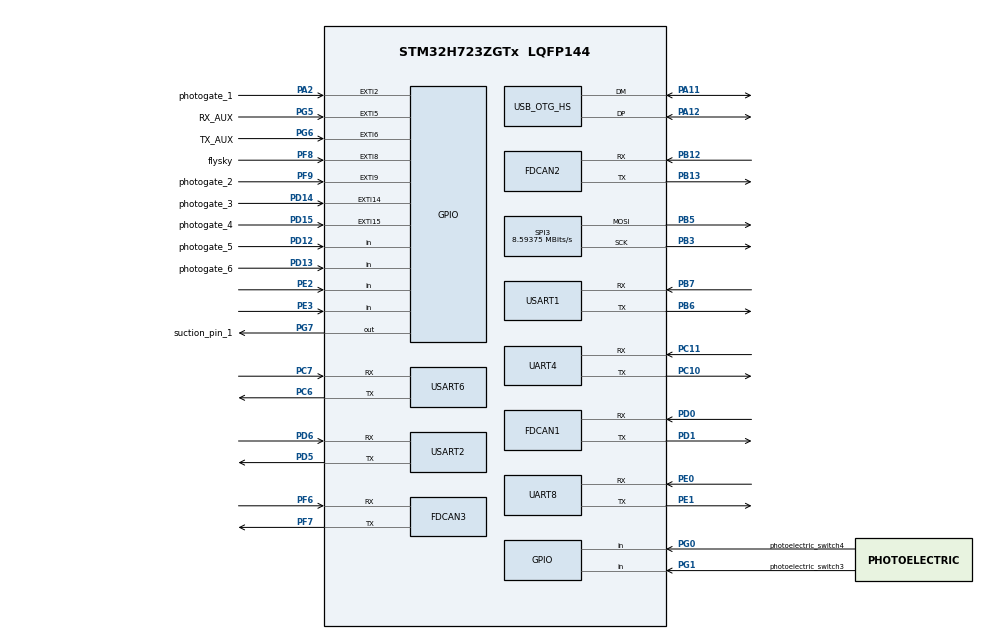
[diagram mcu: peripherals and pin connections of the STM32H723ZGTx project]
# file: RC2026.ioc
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CORTEX_M7.AccessPermission_S-Cortex_Memory_Protection_Unit_Region1_Settings_S=MPU_REGION_PRIV_RO
CORTEX_M7.AccessPermission_S-Cortex_Memory_Protection_Unit_Region2_Settings_S=MPU_REGION_PRIV_RW
CORTEX_M7.AccessPermission_Spec=MPU_REGION_NO_ACCESS
CORTEX_M7.BaseAddress_S-Cortex_Memory_Protection_Unit_Region1_Settings_S=0x08000000
CORTEX_M7.BaseAddress_S-Cortex_Memory_Protection_Unit_Region2_Settings_S=0x20000000
CORTEX_M7.BaseAddress_Spec=0x00000000
CORTEX_M7.CPU_DCache=Enabled
CORTEX_M7.CPU_ICache=Enabled
CORTEX_M7.DisableExec_S-Cortex_Memory_Protection_Unit_Region2_Settings_S=MPU_INSTRUCTION_ACCESS_DISABLE
CORTEX_M7.Enable_S-Cortex_Memory_Protection_Unit_Region1_Settings_S=MPU_REGION_ENABLE
CORTEX_M7.Enable_S-Cortex_Memory_Protection_Unit_Region2_Settings_S=MPU_REGION_ENABLE
CORTEX_M7.IsBufferable_S-Cortex_Memory_Protection_Unit_Region2_Settings_S=MPU_ACCESS_BUFFERABLE
CORTEX_M7.IsCacheable_S-Cortex_Memory_Protection_Unit_Region1_Settings_S=MPU_ACCESS_CACHEABLE
CORTEX_M7.IsCacheable_S-Cortex_Memory_Protection_Unit_Region2_Settings_S=MPU_ACCESS_CACHEABLE
CORTEX_M7.IsCacheable_Spec=MPU_ACCESS_NOT_CACHEABLE
CORTEX_M7.Size_S-Cortex_Memory_Protection_Unit_Region1_Settings_S=MPU_REGION_SIZE_1MB
CORTEX_M7.Size_S-Cortex_Memory_Protection_Unit_Region2_Settings_S=MPU_REGION_SIZE_512KB
CORTEX_M7.Size_Spec=MPU_REGION_SIZE_4GB
CORTEX_M7.SubRegionDisable_Spec=0x87
CORTEX_M7.TypeExtField_S-Cortex_Memory_Protection_Unit_Region1_Settings_S=MPU_TEX_LEVEL1
CORTEX_M7.TypeExtField_S-Cortex_Memory_Protection_Unit_Region2_Settings_S=MPU_TEX_LEVEL1
CORTEX_M7.TypeExtField_Spec=MPU_TEX_LEVEL0
CORTEX_M7.default_mode_Activation=1
Dma.CORDIC_RD.2.Direction=DMA_PERIPH_TO_MEMORY
Dma.CORDIC_RD.2.EventEnable=DISABLE
Dma.CORDIC_RD.2.FIFOMode=DMA_FIFOMODE_DISABLE
Dma.CORDIC_RD.2.Instance=DMA1_Stream4
Dma.CORDIC_RD.2.MemDataAlignment=DMA_MDATAALIGN_BYTE
Dma.CORDIC_RD.2.MemInc=DMA_MINC_ENABLE
Dma.CORDIC_RD.2.Mode=DMA_NORMAL
Dma.CORDIC_RD.2.PeriphDataAlignment=DMA_PDATAALIGN_BYTE
Dma.CORDIC_RD.2.PeriphInc=DMA_PINC_DISABLE
Dma.CORDIC_RD.2.Polarity=HAL_DMAMUX_REQ_GEN_RISING
Dma.CORDIC_RD.2.Priority=DMA_PRIORITY_LOW
Dma.CORDIC_RD.2.RequestNumber=1
Dma.CORDIC_RD.2.SignalID=NONE
Dma.CORDIC_RD.2.SyncEnable=DISABLE
Dma.CORDIC_RD.2.SyncPolarity=HAL_DMAMUX_SYNC_NO_EVENT
Dma.CORDIC_RD.2.SyncRequestNumber=1
Dma.CORDIC_RD.2.SyncSignalID=NONE
Dma.CORDIC_WR.3.Direction=DMA_MEMORY_TO_PERIPH
Dma.CORDIC_WR.3.EventEnable=DISABLE
Dma.CORDIC_WR.3.FIFOMode=DMA_FIFOMODE_DISABLE
Dma.CORDIC_WR.3.Instance=DMA1_Stream5
Dma.CORDIC_WR.3.MemDataAlignment=DMA_MDATAALIGN_BYTE
Dma.CORDIC_WR.3.MemInc=DMA_MINC_ENABLE
Dma.CORDIC_WR.3.Mode=DMA_NORMAL
Dma.CORDIC_WR.3.PeriphDataAlignment=DMA_PDATAALIGN_BYTE
Dma.CORDIC_WR.3.PeriphInc=DMA_PINC_DISABLE
Dma.CORDIC_WR.3.Polarity=HAL_DMAMUX_REQ_GEN_RISING
Dma.CORDIC_WR.3.Priority=DMA_PRIORITY_LOW
Dma.CORDIC_WR.3.RequestNumber=1
Dma.CORDIC_WR.3.SignalID=NONE
Dma.CORDIC_WR.3.SyncEnable=DISABLE
Dma.CORDIC_WR.3.SyncPolarity=HAL_DMAMUX_SYNC_NO_EVENT
Dma.CORDIC_WR.3.SyncRequestNumber=1
Dma.CORDIC_WR.3.SyncSignalID=NONE
Dma.Request0=USART1_RX
Dma.Request1=USART1_TX
Dma.Request10=UART4_RX
Dma.Request11=UART4_TX
Dma.Request12=SPI3_TX
Dma.Request2=CORDIC_RD
Dma.Request3=CORDIC_WR
Dma.Request4=UART8_RX
Dma.Request5=UART8_TX
Dma.Request6=USART2_RX
Dma.Request7=USART2_TX
Dma.Request8=USART6_RX
Dma.Request9=USART6_TX
Dma.SPI3_TX.12.Direction=DMA_MEMORY_TO_PERIPH
Dma.SPI3_TX.12.EventEnable=DISABLE
Dma.SPI3_TX.12.FIFOMode=DMA_FIFOMODE_DISABLE
Dma.SPI3_TX.12.Instance=DMA2_Stream4
Dma.SPI3_TX.12.MemDataAlignment=DMA_MDATAALIGN_BYTE
Dma.SPI3_TX.12.MemInc=DMA_MINC_ENABLE
Dma.SPI3_TX.12.Mode=DMA_NORMAL
Dma.SPI3_TX.12.PeriphDataAlignment=DMA_PDATAALIGN_BYTE
Dma.SPI3_TX.12.PeriphInc=DMA_PINC_DISABLE
Dma.SPI3_TX.12.Polarity=HAL_DMAMUX_REQ_GEN_RISING
Dma.SPI3_TX.12.Priority=DMA_PRIORITY_LOW
Dma.SPI3_TX.12.RequestNumber=1
Dma.SPI3_TX.12.SignalID=NONE
Dma.SPI3_TX.12.SyncEnable=DISABLE
Dma.SPI3_TX.12.SyncPolarity=HAL_DMAMUX_SYNC_NO_EVENT
Dma.SPI3_TX.12.SyncRequestNumber=1
Dma.SPI3_TX.12.SyncSignalID=NONE
Dma.UART4_RX.10.Direction=DMA_PERIPH_TO_MEMORY
Dma.UART4_RX.10.EventEnable=DISABLE
Dma.UART4_RX.10.FIFOMode=DMA_FIFOMODE_DISABLE
Dma.UART4_RX.10.Instance=DMA1_Stream2
Dma.UART4_RX.10.MemDataAlignment=DMA_MDATAALIGN_BYTE
Dma.UART4_RX.10.MemInc=DMA_MINC_ENABLE
Dma.UART4_RX.10.Mode=DMA_NORMAL
Dma.UART4_RX.10.PeriphDataAlignment=DMA_PDATAALIGN_BYTE
Dma.UART4_RX.10.PeriphInc=DMA_PINC_DISABLE
Dma.UART4_RX.10.Polarity=HAL_DMAMUX_REQ_GEN_RISING
Dma.UART4_RX.10.Priority=DMA_PRIORITY_LOW
Dma.UART4_RX.10.RequestNumber=1
Dma.UART4_RX.10.SignalID=NONE
Dma.UART4_RX.10.SyncEnable=DISABLE
Dma.UART4_RX.10.SyncPolarity=HAL_DMAMUX_SYNC_NO_EVENT
Dma.UART4_RX.10.SyncRequestNumber=1
Dma.UART4_RX.10.SyncSignalID=NONE
Dma.UART4_TX.11.Direction=DMA_MEMORY_TO_PERIPH
Dma.UART4_TX.11.EventEnable=DISABLE
Dma.UART4_TX.11.FIFOMode=DMA_FIFOMODE_DISABLE
Dma.UART4_TX.11.Instance=DMA1_Stream3
Dma.UART4_TX.11.MemDataAlignment=DMA_MDATAALIGN_BYTE
Dma.UART4_TX.11.MemInc=DMA_MINC_ENABLE
Dma.UART4_TX.11.Mode=DMA_NORMAL
Dma.UART4_TX.11.PeriphDataAlignment=DMA_PDATAALIGN_BYTE
Dma.UART4_TX.11.PeriphInc=DMA_PINC_DISABLE
Dma.UART4_TX.11.Polarity=HAL_DMAMUX_REQ_GEN_RISING
Dma.UART4_TX.11.Priority=DMA_PRIORITY_LOW
Dma.UART4_TX.11.RequestNumber=1
Dma.UART4_TX.11.SignalID=NONE
Dma.UART4_TX.11.SyncEnable=DISABLE
Dma.UART4_TX.11.SyncPolarity=HAL_DMAMUX_SYNC_NO_EVENT
Dma.UART4_TX.11.SyncRequestNumber=1
Dma.UART4_TX.11.SyncSignalID=NONE
Dma.UART8_RX.4.Direction=DMA_PERIPH_TO_MEMORY
Dma.UART8_RX.4.EventEnable=DISABLE
Dma.UART8_RX.4.FIFOMode=DMA_FIFOMODE_DISABLE
Dma.UART8_RX.4.Instance=DMA1_Stream6
Dma.UART8_RX.4.MemDataAlignment=DMA_MDATAALIGN_BYTE
Dma.UART8_RX.4.MemInc=DMA_MINC_ENABLE
Dma.UART8_RX.4.Mode=DMA_NORMAL
Dma.UART8_RX.4.PeriphDataAlignment=DMA_PDATAALIGN_BYTE
Dma.UART8_RX.4.PeriphInc=DMA_PINC_DISABLE
Dma.UART8_RX.4.Polarity=HAL_DMAMUX_REQ_GEN_RISING
Dma.UART8_RX.4.Priority=DMA_PRIORITY_LOW
Dma.UART8_RX.4.RequestNumber=1
Dma.UART8_RX.4.SignalID=NONE
Dma.UART8_RX.4.SyncEnable=DISABLE
Dma.UART8_RX.4.SyncPolarity=HAL_DMAMUX_SYNC_NO_EVENT
Dma.UART8_RX.4.SyncRequestNumber=1
Dma.UART8_RX.4.SyncSignalID=NONE
Dma.UART8_TX.5.Direction=DMA_MEMORY_TO_PERIPH
Dma.UART8_TX.5.EventEnable=DISABLE
Dma.UART8_TX.5.FIFOMode=DMA_FIFOMODE_DISABLE
Dma.UART8_TX.5.Instance=DMA1_Stream7
Dma.UART8_TX.5.MemDataAlignment=DMA_MDATAALIGN_BYTE
Dma.UART8_TX.5.MemInc=DMA_MINC_ENABLE
Dma.UART8_TX.5.Mode=DMA_NORMAL
Dma.UART8_TX.5.PeriphDataAlignment=DMA_PDATAALIGN_BYTE
Dma.UART8_TX.5.PeriphInc=DMA_PINC_DISABLE
Dma.UART8_TX.5.Polarity=HAL_DMAMUX_REQ_GEN_RISING
Dma.UART8_TX.5.Priority=DMA_PRIORITY_LOW
Dma.UART8_TX.5.RequestNumber=1
Dma.UART8_TX.5.SignalID=NONE
Dma.UART8_TX.5.SyncEnable=DISABLE
Dma.UART8_TX.5.SyncPolarity=HAL_DMAMUX_SYNC_NO_EVENT
Dma.UART8_TX.5.SyncRequestNumber=1
Dma.UART8_TX.5.SyncSignalID=NONE
Dma.USART1_RX.0.Direction=DMA_PERIPH_TO_MEMORY
Dma.USART1_RX.0.EventEnable=DISABLE
Dma.USART1_RX.0.FIFOMode=DMA_FIFOMODE_DISABLE
Dma.USART1_RX.0.Instance=DMA1_Stream0
Dma.USART1_RX.0.MemDataAlignment=DMA_MDATAALIGN_BYTE
Dma.USART1_RX.0.MemInc=DMA_MINC_ENABLE
Dma.USART1_RX.0.Mode=DMA_NORMAL
Dma.USART1_RX.0.PeriphDataAlignment=DMA_PDATAALIGN_BYTE
Dma.USART1_RX.0.PeriphInc=DMA_PINC_DISABLE
Dma.USART1_RX.0.Polarity=HAL_DMAMUX_REQ_GEN_RISING
Dma.USART1_RX.0.Priority=DMA_PRIORITY_LOW
Dma.USART1_RX.0.RequestNumber=1
Dma.USART1_RX.0.SignalID=NONE
Dma.USART1_RX.0.SyncEnable=DISABLE
Dma.USART1_RX.0.SyncPolarity=HAL_DMAMUX_SYNC_NO_EVENT
Dma.USART1_RX.0.SyncRequestNumber=1
Dma.USART1_RX.0.SyncSignalID=NONE
Dma.USART1_TX.1.Direction=DMA_MEMORY_TO_PERIPH
Dma.USART1_TX.1.EventEnable=DISABLE
Dma.USART1_TX.1.FIFOMode=DMA_FIFOMODE_DISABLE
Dma.USART1_TX.1.Instance=DMA1_Stream1
Dma.USART1_TX.1.MemDataAlignment=DMA_MDATAALIGN_BYTE
Dma.USART1_TX.1.MemInc=DMA_MINC_ENABLE
Dma.USART1_TX.1.Mode=DMA_NORMAL
Dma.USART1_TX.1.PeriphDataAlignment=DMA_PDATAALIGN_BYTE
Dma.USART1_TX.1.PeriphInc=DMA_PINC_DISABLE
Dma.USART1_TX.1.Polarity=HAL_DMAMUX_REQ_GEN_RISING
Dma.USART1_TX.1.Priority=DMA_PRIORITY_LOW
Dma.USART1_TX.1.RequestNumber=1
Dma.USART1_TX.1.SignalID=NONE
Dma.USART1_TX.1.SyncEnable=DISABLE
Dma.USART1_TX.1.SyncPolarity=HAL_DMAMUX_SYNC_NO_EVENT
Dma.USART1_TX.1.SyncRequestNumber=1
Dma.USART1_TX.1.SyncSignalID=NONE
Dma.USART2_RX.6.Direction=DMA_PERIPH_TO_MEMORY
Dma.USART2_RX.6.EventEnable=DISABLE
Dma.USART2_RX.6.FIFOMode=DMA_FIFOMODE_DISABLE
Dma.USART2_RX.6.Instance=DMA2_Stream0
Dma.USART2_RX.6.MemDataAlignment=DMA_MDATAALIGN_BYTE
Dma.USART2_RX.6.MemInc=DMA_MINC_ENABLE
Dma.USART2_RX.6.Mode=DMA_NORMAL
Dma.USART2_RX.6.PeriphDataAlignment=DMA_PDATAALIGN_BYTE
Dma.USART2_RX.6.PeriphInc=DMA_PINC_DISABLE
Dma.USART2_RX.6.Polarity=HAL_DMAMUX_REQ_GEN_RISING
Dma.USART2_RX.6.Priority=DMA_PRIORITY_LOW
Dma.USART2_RX.6.RequestNumber=1
Dma.USART2_RX.6.SignalID=NONE
Dma.USART2_RX.6.SyncEnable=DISABLE
Dma.USART2_RX.6.SyncPolarity=HAL_DMAMUX_SYNC_NO_EVENT
Dma.USART2_RX.6.SyncRequestNumber=1
Dma.USART2_RX.6.SyncSignalID=NONE
Dma.USART2_TX.7.Direction=DMA_MEMORY_TO_PERIPH
Dma.USART2_TX.7.EventEnable=DISABLE
Dma.USART2_TX.7.FIFOMode=DMA_FIFOMODE_DISABLE
Dma.USART2_TX.7.Instance=DMA2_Stream1
Dma.USART2_TX.7.MemDataAlignment=DMA_MDATAALIGN_BYTE
Dma.USART2_TX.7.MemInc=DMA_MINC_ENABLE
Dma.USART2_TX.7.Mode=DMA_NORMAL
Dma.USART2_TX.7.PeriphDataAlignment=DMA_PDATAALIGN_BYTE
Dma.USART2_TX.7.PeriphInc=DMA_PINC_DISABLE
Dma.USART2_TX.7.Polarity=HAL_DMAMUX_REQ_GEN_RISING
Dma.USART2_TX.7.Priority=DMA_PRIORITY_LOW
Dma.USART2_TX.7.RequestNumber=1
Dma.USART2_TX.7.SignalID=NONE
Dma.USART2_TX.7.SyncEnable=DISABLE
Dma.USART2_TX.7.SyncPolarity=HAL_DMAMUX_SYNC_NO_EVENT
Dma.USART2_TX.7.SyncRequestNumber=1
Dma.USART2_TX.7.SyncSignalID=NONE
Dma.USART6_RX.8.Direction=DMA_PERIPH_TO_MEMORY
Dma.USART6_RX.8.EventEnable=DISABLE
Dma.USART6_RX.8.FIFOMode=DMA_FIFOMODE_DISABLE
Dma.USART6_RX.8.Instance=DMA2_Stream2
Dma.USART6_RX.8.MemDataAlignment=DMA_MDATAALIGN_BYTE
Dma.USART6_RX.8.MemInc=DMA_MINC_ENABLE
Dma.USART6_RX.8.Mode=DMA_NORMAL
Dma.USART6_RX.8.PeriphDataAlignment=DMA_PDATAALIGN_BYTE
Dma.USART6_RX.8.PeriphInc=DMA_PINC_DISABLE
Dma.USART6_RX.8.Polarity=HAL_DMAMUX_REQ_GEN_RISING
Dma.USART6_RX.8.Priority=DMA_PRIORITY_LOW
Dma.USART6_RX.8.RequestNumber=1
Dma.USART6_RX.8.SignalID=NONE
Dma.USART6_RX.8.SyncEnable=DISABLE
Dma.USART6_RX.8.SyncPolarity=HAL_DMAMUX_SYNC_NO_EVENT
Dma.USART6_RX.8.SyncRequestNumber=1
Dma.USART6_RX.8.SyncSignalID=NONE
Dma.USART6_TX.9.Direction=DMA_MEMORY_TO_PERIPH
Dma.USART6_TX.9.EventEnable=DISABLE
Dma.USART6_TX.9.FIFOMode=DMA_FIFOMODE_DISABLE
Dma.USART6_TX.9.Instance=DMA2_Stream3
Dma.USART6_TX.9.MemDataAlignment=DMA_MDATAALIGN_BYTE
Dma.USART6_TX.9.MemInc=DMA_MINC_ENABLE
Dma.USART6_TX.9.Mode=DMA_NORMAL
Dma.USART6_TX.9.PeriphDataAlignment=DMA_PDATAALIGN_BYTE
Dma.USART6_TX.9.PeriphInc=DMA_PINC_DISABLE
Dma.USART6_TX.9.Polarity=HAL_DMAMUX_REQ_GEN_RISING
Dma.USART6_TX.9.Priority=DMA_PRIORITY_LOW
Dma.USART6_TX.9.RequestNumber=1
Dma.USART6_TX.9.SignalID=NONE
Dma.USART6_TX.9.SyncEnable=DISABLE
Dma.USART6_TX.9.SyncPolarity=HAL_DMAMUX_SYNC_NO_EVENT
Dma.USART6_TX.9.SyncRequestNumber=1
Dma.USART6_TX.9.SyncSignalID=NONE
FDCAN1.CalculateBaudRateNominal=1000000
FDCAN1.CalculateTimeBitNominal=1000
FDCAN1.CalculateTimeQuantumNominal=40.0
FDCAN1.DataPrescaler=1
FDCAN1.DataSyncJumpWidth=2
FDCAN1.DataTimeSeg1=15
FDCAN1.DataTimeSeg2=9
FDCAN1.ExtFiltersNbr=2
FDCAN1.NominalPrescaler=1
FDCAN1.NominalSyncJumpWidth=2
FDCAN1.NominalTimeSeg1=15
FDCAN1.NominalTimeSeg2=9
FDCAN1.ProtocolException=DISABLE
FDCAN1.RxBuffersNbr=0
FDCAN1.RxFifo0ElmtsNbr=8
FDCAN1.RxFifo1ElmtsNbr=8
FDCAN1.StdFiltersNbr=2
FDCAN1.TxBuffersNbr=29
FDCAN1.TxFifoQueueElmtsNbr=3
FDCAN2.CalculateBaudRateNominal=1000000
FDCAN2.CalculateTimeBitNominal=1000
FDCAN2.CalculateTimeQuantumNominal=40.0
FDCAN2.DataPrescaler=1
FDCAN2.DataSyncJumpWidth=2
FDCAN2.DataTimeSeg1=15
FDCAN2.DataTimeSeg2=9
FDCAN2.ExtFiltersNbr=2
FDCAN2.MessageRAMOffset=0x400
FDCAN2.NominalPrescaler=1
FDCAN2.NominalSyncJumpWidth=2
FDCAN2.NominalTimeSeg1=15
FDCAN2.NominalTimeSeg2=9
FDCAN2.ProtocolException=DISABLE
FDCAN2.RxBuffersNbr=0
FDCAN2.RxFifo0ElmtsNbr=8
FDCAN2.RxFifo1ElmtsNbr=8
FDCAN2.StdFiltersNbr=2
FDCAN2.TxBuffersNbr=29
FDCAN2.TxFifoQueueElmtsNbr=3
FDCAN3.CalculateBaudRateNominal=1000000
FDCAN3.CalculateTimeBitNominal=1000
FDCAN3.CalculateTimeQuantumNominal=40.0
FDCAN3.DataSyncJumpWidth=2
FDCAN3.DataTimeSeg1=15
FDCAN3.DataTimeSeg2=9
FDCAN3.ExtFiltersNbr=2
FDCAN3.MessageRAMOffset=0x800
FDCAN3.NominalPrescaler=1
FDCAN3.NominalSyncJumpWidth=2
FDCAN3.NominalTimeSeg1=15
FDCAN3.NominalTimeSeg2=9
FDCAN3.RxBuffersNbr=0
FDCAN3.RxFifo0ElmtsNbr=8
FDCAN3.RxFifo1ElmtsNbr=8
FDCAN3.StdFiltersNbr=2
FDCAN3.TxBuffersNbr=29
FDCAN3.TxFifoQueueElmtsNbr=3
FREERTOS.Tasks01=defaultTask,24,128,StartDefaultTask,Default,NULL,Dynamic,NULL,NULL
Mcu.Family=STM32H7
Mcu.Name=STM32H723ZGTx
Mcu.Package=LQFP144
NVIC.CORDIC_IRQn=true\:5\:0\:false\:false\:true\:true\:true\:true\:true
NVIC.DMA1_Stream0_IRQn=true\:5\:0\:false\:false\:true\:true\:false\:true\:true
NVIC.DMA1_Stream1_IRQn=true\:5\:0\:false\:false\:true\:true\:false\:true\:true
NVIC.DMA1_Stream2_IRQn=true\:5\:0\:false\:false\:true\:true\:false\:true\:true
NVIC.DMA1_Stream3_IRQn=true\:5\:0\:false\:false\:true\:true\:false\:true\:true
NVIC.DMA1_Stream4_IRQn=true\:5\:0\:false\:false\:true\:true\:false\:true\:true
NVIC.DMA1_Stream5_IRQn=true\:5\:0\:false\:false\:true\:true\:false\:true\:true
NVIC.DMA1_Stream6_IRQn=true\:5\:0\:false\:false\:true\:true\:false\:true\:true
NVIC.DMA1_Stream7_IRQn=true\:5\:0\:false\:false\:true\:true\:false\:true\:true
NVIC.DMA2_Stream0_IRQn=true\:5\:0\:false\:false\:true\:true\:false\:true\:true
NVIC.DMA2_Stream1_IRQn=true\:5\:0\:false\:false\:true\:true\:false\:true\:true
NVIC.DMA2_Stream2_IRQn=true\:5\:0\:false\:false\:true\:true\:false\:true\:true
NVIC.DMA2_Stream3_IRQn=true\:5\:0\:false\:false\:true\:true\:false\:true\:true
NVIC.DMA2_Stream4_IRQn=true\:5\:0\:false\:false\:true\:true\:false\:true\:true
NVIC.EXTI15_10_IRQn=true\:4\:0\:true\:false\:true\:false\:true\:true\:true
NVIC.EXTI2_IRQn=true\:4\:0\:true\:false\:true\:false\:true\:true\:true
NVIC.EXTI9_5_IRQn=true\:4\:0\:true\:false\:true\:false\:true\:true\:true
NVIC.FDCAN1_IT0_IRQn=true\:5\:0\:false\:false\:true\:true\:true\:true\:true
NVIC.FDCAN1_IT1_IRQn=true\:5\:0\:false\:false\:true\:true\:true\:true\:true
NVIC.FDCAN2_IT0_IRQn=true\:5\:0\:false\:false\:true\:true\:true\:true\:true
NVIC.FDCAN2_IT1_IRQn=true\:5\:0\:false\:false\:true\:true\:true\:true\:true
NVIC.FDCAN3_IT0_IRQn=true\:5\:0\:false\:false\:true\:true\:true\:true\:true
NVIC.FDCAN3_IT1_IRQn=true\:5\:0\:false\:false\:true\:true\:true\:true\:true
NVIC.OTG_HS_IRQn=true\:5\:0\:false\:false\:true\:true\:false\:true\:true
NVIC.PriorityGroup=NVIC_PRIORITYGROUP_4
NVIC.SPI3_IRQn=true\:5\:0\:false\:false\:true\:true\:false\:true\:true
NVIC.TIM2_IRQn=true\:5\:0\:false\:false\:true\:true\:true\:true\:true
NVIC.TIM4_IRQn=true\:3\:0\:true\:false\:true\:false\:true\:true\:true
NVIC.TIM6_DAC_IRQn=true\:15\:0\:false\:false\:true\:false\:false\:true\:true
NVIC.TIM7_IRQn=true\:7\:0\:true\:false\:true\:false\:true\:true\:true
NVIC.TIM8_UP_TIM13_IRQn=true\:7\:0\:true\:false\:true\:false\:true\:true\:true
NVIC.TimeBase=TIM6_DAC_IRQn
NVIC.TimeBaseIP=TIM6
NVIC.UART4_IRQn=true\:5\:0\:false\:false\:true\:true\:true\:true\:true
NVIC.UART8_IRQn=true\:5\:0\:false\:false\:true\:true\:true\:true\:true
NVIC.USART1_IRQn=true\:5\:0\:false\:false\:true\:false\:true\:true\:true
NVIC.USART2_IRQn=true\:5\:0\:false\:false\:true\:true\:true\:true\:true
NVIC.USART6_IRQn=true\:5\:0\:false\:false\:true\:true\:true\:true\:true
PA11.Mode=Device_Only_FS
PA11.Signal=USB_OTG_HS_DM
PA12.Mode=Device_Only_FS
PA12.Signal=USB_OTG_HS_DP
PA13(JTMS/SWDIO).Mode=Serial_Wire
PA13(JTMS/SWDIO).Signal=DEBUG_JTMS-SWDIO
PA14(JTCK/SWCLK).Mode=Serial_Wire
PA14(JTCK/SWCLK).Signal=DEBUG_JTCK-SWCLK
PA2.GPIO_Label=photogate_1
PA2.GPIO_PuPd=GPIO_PULLUP
PA2.Signal=GPXTI2
PB12.Mode=FDCAN_Activate
PB12.Signal=FDCAN2_RX
PB13.Mode=FDCAN_Activate
PB13.Signal=FDCAN2_TX
PB3(JTDO/TRACESWO).GPIO_Speed=GPIO_SPEED_FREQ_VERY_HIGH
PB3(JTDO/TRACESWO).Mode=TX_Only_Simplex_Unidirect_Master
PB3(JTDO/TRACESWO).Signal=SPI3_SCK
PB5.GPIO_Speed=GPIO_SPEED_FREQ_VERY_HIGH
PB5.Mode=TX_Only_Simplex_Unidirect_Master
PB5.Signal=SPI3_MOSI
PB6.Mode=Asynchronous
PB6.Signal=USART1_TX
PB7.Mode=Asynchronous
PB7.Signal=USART1_RX
PC10.Mode=Asynchronous
PC10.Signal=UART4_TX
PC11.Mode=Asynchronous
PC11.Signal=UART4_RX
PC6.Mode=Asynchronous
PC6.Signal=USART6_TX
PC7.Mode=Asynchronous
PC7.Signal=USART6_RX
PD0.Mode=FDCAN_Activate
PD0.Signal=FDCAN1_RX
PD1.Mode=FDCAN_Activate
PD1.Signal=FDCAN1_TX
PD12.GPIO_Label=photogate_5
PD12.GPIO_PuPd=GPIO_PULLUP
PD12.Signal=GPIO_Input
PD13.GPIO_Label=photogate_6
PD13.GPIO_PuPd=GPIO_PULLUP
PD13.Signal=GPIO_Input
PD14.GPIO_Label=photogate_3
PD14.GPIO_PuPd=GPIO_PULLUP
PD14.Signal=GPXTI14
PD15.GPIO_Label=photogate_4
PD15.GPIO_PuPd=GPIO_PULLUP
PD15.Signal=GPXTI15
PD5.Mode=Asynchronous
PD5.Signal=USART2_TX
PD6.Mode=Asynchronous
PD6.Signal=USART2_RX
PE0.Mode=Asynchronous
PE0.Signal=UART8_RX
PE1.Mode=Asynchronous
PE1.Signal=UART8_TX
PE2.GPIO_PuPd=GPIO_PULLUP
PE2.Signal=GPIO_Input
PE3.GPIO_PuPd=GPIO_PULLUP
PE3.Signal=GPIO_Input
PF6.Mode=FDCAN_Activate
PF6.Signal=FDCAN3_RX
PF7.Mode=FDCAN_Activate
PF7.Signal=FDCAN3_TX
PF8.GPIO_Label=flysky
PF8.GPIO_PuPd=GPIO_NOPULL
PF8.Signal=GPXTI8
PF9.GPIO_Label=photogate_2
PF9.GPIO_PuPd=GPIO_PULLUP
PF9.Signal=GPXTI9
PG0.GPIO_Label=photoelectric_switch4
PG0.GPIO_PuPd=GPIO_PULLUP
PG0.Signal=GPIO_Input
PG1.GPIO_Label=photoelectric_switch3
PG1.GPIO_PuPd=GPIO_PULLUP
PG1.Signal=GPIO_Input
PG5.GPIO_Label=RX_AUX
PG5.GPIO_PuPd=GPIO_PULLDOWN
PG5.Signal=GPXTI5
PG6.GPIO_Label=TX_AUX
PG6.GPIO_PuPd=GPIO_PULLDOWN
PG6.Signal=GPXTI6
PG7.GPIO_Label=suction_pin_1
PG7.GPIO_ModeDefaultOutputPP=GPIO_MODE_OUTPUT_PP
PG7.GPIO_Speed=GPIO_SPEED_FREQ_HIGH
PG7.PinState=GPIO_PIN_RESET
PG7.Signal=GPIO_Output
PH0-OSC_IN.Mode=HSE-External-Oscillator
PH0-OSC_IN.Signal=RCC_OSC_IN
PH1-OSC_OUT.Mode=HSE-External-Oscillator
PH1-OSC_OUT.Signal=RCC_OSC_OUT
ProjectManager.HeapSize=0x200
ProjectManager.StackSize=0x400
ProjectManager.TargetToolchain=MDK-ARM V5.32
RCC.ADCFreq_Value=50390625
RCC.APB1Freq_Value=137500000
RCC.APB2Freq_Value=137500000
RCC.APB3Freq_Value=137500000
RCC.APB4Freq_Value=137500000
RCC.CortexFreq_Value=550000000
RCC.D1PPRE=RCC_APB3_DIV2
RCC.D2PPRE1=RCC_APB1_DIV2
RCC.D2PPRE2=RCC_APB2_DIV2
RCC.D3PPRE=RCC_APB4_DIV2
RCC.DIVM1=2
RCC.DIVN1=44
RCC.DIVP1=1
RCC.DIVQ1=4
RCC.FDCANCLockSelection=RCC_FDCANCLKSOURCE_HSE
RCC.HCLKFreq_Value=275000000
RCC.HPRE=RCC_HCLK_DIV2
RCC.PLL2FRACN=0
RCC.PLL3FRACN=0
RCC.PLLFRACN=0
RCC.PLLSourceVirtual=RCC_PLLSOURCE_HSE
RCC.SYSCLKFreq_VALUE=550000000
RCC.SYSCLKSource=RCC_SYSCLKSOURCE_PLLCLK
RCC.USBCLockSelection=RCC_USBCLKSOURCE_HSI48
RCC.USBFreq_Value=48000000
SPI3.BaudRatePrescaler=SPI_BAUDRATEPRESCALER_16
SPI3.CalculateBaudRate=8.59375 MBits/s
SPI3.DataSize=SPI_DATASIZE_8BIT
SPI3.Direction=SPI_DIRECTION_2LINES_TXONLY
SPI3.Mode=SPI_MODE_MASTER
SPI3.NSSPMode=SPI_NSS_PULSE_DISABLE
SPI3.VirtualType=VM_MASTER
TIM13.Period=2000 - 1
TIM13.Prescaler=275 - 1
TIM2.Prescaler=275 - 1
TIM4.Period=2000 - 1
TIM4.Prescaler=275 - 1
TIM7.Period=1000 - 1
TIM7.Prescaler=275 - 1
USART1.DMADisableonRxErrorParam=ADVFEATURE_DMA_ENABLEONRXERROR
USART1.FIFOMode=FIFOMODE_ENABLE
USART1.OverrunDisableParam=ADVFEATURE_OVERRUN_DISABLE
USART1.VirtualMode-Asynchronous=VM_ASYNC
USART2.VirtualMode-Asynchronous=VM_ASYNC
USART6.VirtualMode-Asynchronous=VM_ASYNC
USB_DEVICE.APP_RX_DATA_SIZE=512
USB_DEVICE.APP_TX_DATA_SIZE=512
USB_DEVICE.CLASS_NAME_HS=CDC
USB_DEVICE.VirtualMode=Cdc
USB_DEVICE.VirtualModeHS=Cdc_HS
USB_OTG_HS.VirtualMode-Device_Only_FS=Device_Only_FS
USB_OTG_HS.dma_enable-Device_Only_FS=DISABLE
VP_CORDIC_VS_CORDIC.Mode=CORDIC_Activate
VP_FREERTOS_VS_CMSIS_V2.Mode=CMSIS_V2
VP_MEMORYMAP_VS_MEMORYMAP.Mode=CurAppReg
VP_SYS_VS_tim6.Mode=TIM6
VP_TIM13_VS_ClockSourceINT.Mode=Enable_Timer
VP_TIM2_VS_ClockSourceINT.Mode=Internal
VP_TIM4_VS_ClockSourceINT.Mode=Internal
VP_TIM7_VS_ClockSourceINT.Mode=Enable_Timer
VP_USB_DEVICE_VS_USB_DEVICE_CDC_HS.Mode=CDC_HS
board=custom

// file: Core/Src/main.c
/* USER CODE BEGIN Header */
/**
  ******************************************************************************
  * @file           : main.c
  * @brief          : Main program body
  ******************************************************************************
  * @attention
  *
  * Copyright (c) 2025 STMicroelectronics.
  * All rights reserved.
  *
  * This software is licensed under terms that can be found in the LICENSE file
  * in the root directory of this software component.
  * If no LICENSE file comes with this software, it is provided AS-IS.
  *
  ******************************************************************************
  */
/* USER CODE END Header */
#include "main.h"
#include "cmsis_os.h"
#include "cordic.h"
#include "dma.h"
#include "fdcan.h"
#include "spi.h"
#include "tim.h"
#include "usart.h"
#include "usb_device.h"
#include "gpio.h"

/* USER CODE BEGIN Includes */
#include "RC_init.h"
/* USER CODE END Includes */

void SystemClock_Config(void);
static void MPU_Config(void);
void MX_FREERTOS_Init(void);

int main(void)
{

  /* MPU Configuration--------------------------------------------------------*/
  MPU_Config();

  /* Enable the CPU Cache */

  /* Enable I-Cache---------------------------------------------------------*/
  SCB_EnableICache();

  /* Enable D-Cache---------------------------------------------------------*/
  SCB_EnableDCache();

  /* MCU Configuration--------------------------------------------------------*/

  /* Reset of all peripherals, Initializes the Flash interface and the Systick. */
  HAL_Init();

  /* Configure the system clock */
  SystemClock_Config();

  /* Initialize all configured peripherals */
  MX_GPIO_Init();
  MX_DMA_Init();
  MX_FDCAN1_Init();
  MX_FDCAN2_Init();
  MX_FDCAN3_Init();
  MX_TIM4_Init();
  MX_TIM7_Init();
  MX_USART1_UART_Init();
  MX_TIM13_Init();
  MX_CORDIC_Init();
  MX_TIM2_Init();
  MX_UART8_Init();
  MX_USART2_UART_Init();
  MX_USART6_UART_Init();
  MX_UART4_Init();
  MX_SPI3_Init();
  /* USER CODE BEGIN 2 */
	All_Init();
  /* USER CODE END 2 */

  /* Init scheduler */
  osKernelInitialize();  /* Call init function for freertos objects (in cmsis_os2.c) */
  MX_FREERTOS_Init();

  /* Start scheduler */
  osKernelStart();

  /* We should never get here as control is now taken by the scheduler */

  /* Infinite loop */
  while (1)
  {

  }
}

void SystemClock_Config(void)
{
  RCC_OscInitTypeDef RCC_OscInitStruct = {0};
  RCC_ClkInitTypeDef RCC_ClkInitStruct = {0};

  /** Supply configuration update enable
  */
  HAL_PWREx_ConfigSupply(PWR_LDO_SUPPLY);

  /** Configure the main internal regulator output voltage
  */
  __HAL_PWR_VOLTAGESCALING_CONFIG(PWR_REGULATOR_VOLTAGE_SCALE0);

  while(!__HAL_PWR_GET_FLAG(PWR_FLAG_VOSRDY)) {}

  /** Initializes the RCC Oscillators according to the specified parameters
  * in the RCC_OscInitTypeDef structure.
  */
  RCC_OscInitStruct.OscillatorType = RCC_OSCILLATORTYPE_HSI48|RCC_OSCILLATORTYPE_HSE;
  RCC_OscInitStruct.HSEState = RCC_HSE_ON;
  RCC_OscInitStruct.HSI48State = RCC_HSI48_ON;
  RCC_OscInitStruct.PLL.PLLState = RCC_PLL_ON;
  RCC_OscInitStruct.PLL.PLLSource = RCC_PLLSOURCE_HSE;
  RCC_OscInitStruct.PLL.PLLM = 2;
  RCC_OscInitStruct.PLL.PLLN = 44;
  RCC_OscInitStruct.PLL.PLLP = 1;
  RCC_OscInitStruct.PLL.PLLQ = 4;
  RCC_OscInitStruct.PLL.PLLR = 2;
  RCC_OscInitStruct.PLL.PLLRGE = RCC_PLL1VCIRANGE_3;
  RCC_OscInitStruct.PLL.PLLVCOSEL = RCC_PLL1VCOWIDE;
  RCC_OscInitStruct.PLL.PLLFRACN = 0;
  if (HAL_RCC_OscConfig(&RCC_OscInitStruct) != HAL_OK)
  {
    Error_Handler();
  }

  /** Initializes the CPU, AHB and APB buses clocks
  */
  RCC_ClkInitStruct.ClockType = RCC_CLOCKTYPE_HCLK|RCC_CLOCKTYPE_SYSCLK
                              |RCC_CLOCKTYPE_PCLK1|RCC_CLOCKTYPE_PCLK2
                              |RCC_CLOCKTYPE_D3PCLK1|RCC_CLOCKTYPE_D1PCLK1;
  RCC_ClkInitStruct.SYSCLKSource = RCC_SYSCLKSOURCE_PLLCLK;
  RCC_ClkInitStruct.SYSCLKDivider = RCC_SYSCLK_DIV1;
  RCC_ClkInitStruct.AHBCLKDivider = RCC_HCLK_DIV2;
  RCC_ClkInitStruct.APB3CLKDivider = RCC_APB3_DIV2;
  RCC_ClkInitStruct.APB1CLKDivider = RCC_APB1_DIV2;
  RCC_ClkInitStruct.APB2CLKDivider = RCC_APB2_DIV2;
  RCC_ClkInitStruct.APB4CLKDivider = RCC_APB4_DIV2;

  if (HAL_RCC_ClockConfig(&RCC_ClkInitStruct, FLASH_LATENCY_3) != HAL_OK)
  {
    Error_Handler();
  }
}

 /* MPU Configuration */

void MPU_Config(void)
{
  MPU_Region_InitTypeDef MPU_InitStruct = {0};

  /* Disables the MPU */
  HAL_MPU_Disable();

  /** Initializes and configures the Region and the memory to be protected
  */
  MPU_InitStruct.Enable = MPU_REGION_ENABLE;
  MPU_InitStruct.Number = MPU_REGION_NUMBER0;
  MPU_InitStruct.BaseAddress = 0x00000000;
  MPU_InitStruct.Size = MPU_REGION_SIZE_4GB;
  MPU_InitStruct.SubRegionDisable = 0x87;
  MPU_InitStruct.TypeExtField = MPU_TEX_LEVEL0;
  MPU_InitStruct.AccessPermission = MPU_REGION_NO_ACCESS;
  MPU_InitStruct.DisableExec = MPU_INSTRUCTION_ACCESS_DISABLE;
  MPU_InitStruct.IsShareable = MPU_ACCESS_SHAREABLE;
  MPU_InitStruct.IsCacheable = MPU_ACCESS_NOT_CACHEABLE;
  MPU_InitStruct.IsBufferable = MPU_ACCESS_NOT_BUFFERABLE;

  HAL_MPU_ConfigRegion(&MPU_InitStruct);

  /** Initializes and configures the Region and the memory to be protected
  */
  MPU_InitStruct.Number = MPU_REGION_NUMBER1;
  MPU_InitStruct.BaseAddress = 0x08000000;
  MPU_InitStruct.Size = MPU_REGION_SIZE_1MB;
  MPU_InitStruct.SubRegionDisable = 0x0;
  MPU_InitStruct.TypeExtField = MPU_TEX_LEVEL1;
  MPU_InitStruct.AccessPermission = MPU_REGION_PRIV_RO;
  MPU_InitStruct.DisableExec = MPU_INSTRUCTION_ACCESS_ENABLE;
  MPU_InitStruct.IsShareable = MPU_ACCESS_NOT_SHAREABLE;
  MPU_InitStruct.IsCacheable = MPU_ACCESS_CACHEABLE;

  HAL_MPU_ConfigRegion(&MPU_InitStruct);

  /** Initializes and configures the Region and the memory to be protected
  */
  MPU_InitStruct.Number = MPU_REGION_NUMBER2;
  MPU_InitStruct.BaseAddress = 0x20000000;
  MPU_InitStruct.Size = MPU_REGION_SIZE_512KB;
  MPU_InitStruct.AccessPermission = MPU_REGION_PRIV_RW;
  MPU_InitStruct.DisableExec = MPU_INSTRUCTION_ACCESS_DISABLE;
  MPU_InitStruct.IsBufferable = MPU_ACCESS_BUFFERABLE;

  HAL_MPU_ConfigRegion(&MPU_InitStruct);
  /* Enables the MPU */
  HAL_MPU_Enable(MPU_PRIVILEGED_DEFAULT);

}

void HAL_TIM_PeriodElapsedCallback(TIM_HandleTypeDef *htim)
{
  if (htim->Instance == TIM6)
  {
    HAL_IncTick();
  }
  /* USER CODE BEGIN Callback 1 */
	All_Tim_It_Process(htim);
  /* USER CODE END Callback 1 */
}

void Error_Handler(void)
{
  __disable_irq();
  while (1)
  {
  }
}
